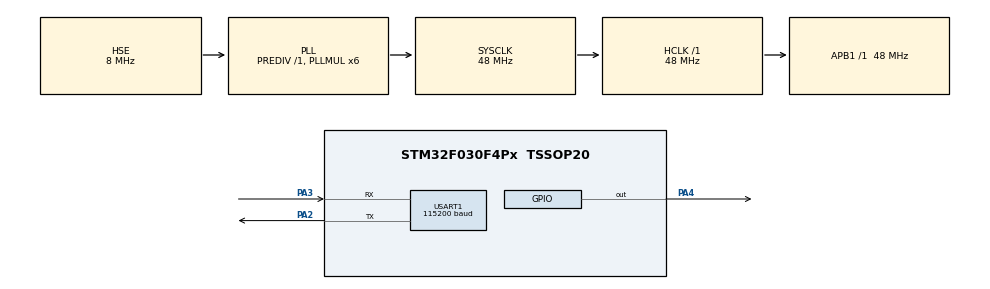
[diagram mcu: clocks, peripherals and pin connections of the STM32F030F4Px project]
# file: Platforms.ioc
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Mcu.Family=STM32F0
Mcu.Name=STM32F030F4Px
Mcu.Package=TSSOP20
NVIC.USART1_IRQn=true\:0\:0\:false
PA13.Mode=Serial-WireDebug
PA13.Signal=SYS_SWDIO
PA14.Mode=Serial-WireDebug
PA14.Signal=SYS_SWCLK
PA2.Mode=Asynchronous
PA2.Signal=USART1_TX
PA3.Mode=Asynchronous
PA3.Signal=USART1_RX
PA4.Signal=GPIO_Output
PF0-OSC_IN.Mode=HSE-External-Oscillator
PF0-OSC_IN.Signal=RCC_OSC_IN
PF1-OSC_OUT.Mode=HSE-External-Oscillator
PF1-OSC_OUT.Signal=RCC_OSC_OUT
ProjectManager.HeapSize=0x200
ProjectManager.StackSize=0x400
ProjectManager.TargetToolchain=MDK-ARM V5
RCC.AHBFreq_Value=48000000
RCC.APB1Freq_Value=48000000
RCC.APB1TimFreq_Value=48000000
RCC.HCLKFreq_Value=48000000
RCC.HSIState=RCC_HSI_ON
RCC.PLLMUL=RCC_PLL_MUL6
RCC.PLLSourceVirtual=RCC_PLLSOURCE_HSE
RCC.SYSCLKFreq_VALUE=48000000
RCC.SYSCLKSource=RCC_SYSCLKSOURCE_PLLCLK
USART1.BaudRate=115200
board=Platforms

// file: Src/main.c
/**
  ******************************************************************************
  * File Name          : main.c
  * Description        : Main program body
  ******************************************************************************
  *
  * COPYRIGHT(c) 2016 STMicroelectronics
  *
  * Redistribution and use in source and binary forms, with or without modification,
  * are permitted provided that the following conditions are met:
  *   1. Redistributions of source code must retain the above copyright notice,
  *      this list of conditions and the following disclaimer.
  *   2. Redistributions in binary form must reproduce the above copyright notice,
  *      this list of conditions and the following disclaimer in the documentation
  *      and/or other materials provided with the distribution.
  *   3. Neither the name of STMicroelectronics nor the names of its contributors
  *      may be used to endorse or promote products derived from this software
  *      without specific prior written permission.
  *
  * THIS SOFTWARE IS PROVIDED BY THE COPYRIGHT HOLDERS AND CONTRIBUTORS "AS IS"
  * AND ANY EXPRESS OR IMPLIED WARRANTIES, INCLUDING, BUT NOT LIMITED TO, THE
  * IMPLIED WARRANTIES OF MERCHANTABILITY AND FITNESS FOR A PARTICULAR PURPOSE ARE
  * DISCLAIMED. IN NO EVENT SHALL THE COPYRIGHT HOLDER OR CONTRIBUTORS BE LIABLE
  * FOR ANY DIRECT, INDIRECT, INCIDENTAL, SPECIAL, EXEMPLARY, OR CONSEQUENTIAL
  * DAMAGES (INCLUDING, BUT NOT LIMITED TO, PROCUREMENT OF SUBSTITUTE GOODS OR
  * SERVICES; LOSS OF USE, DATA, OR PROFITS; OR BUSINESS INTERRUPTION) HOWEVER
  * CAUSED AND ON ANY THEORY OF LIABILITY, WHETHER IN CONTRACT, STRICT LIABILITY,
  * OR TORT (INCLUDING NEGLIGENCE OR OTHERWISE) ARISING IN ANY WAY OUT OF THE USE
  * OF THIS SOFTWARE, EVEN IF ADVISED OF THE POSSIBILITY OF SUCH DAMAGE.
  *
  ******************************************************************************
  */
#include "stm32f0xx_hal.h"

/* USER CODE BEGIN Includes */
#include "main.h"

/* USER CODE END Includes */

UART_HandleTypeDef huart1;

/* USER CODE BEGIN PV */
/* Private variables ---------------------------------------------------------*/
#define APPLICATION_ADDRESS     (uint32_t)0x08001000
#define SYSCFG_MemoryRemap_SRAM                 ((uint8_t)0x03)
/* USER CODE END PV */

void SystemClock_Config(void);
static void MX_GPIO_Init(void);
static void MX_USART1_UART_Init(void);

/* USER CODE BEGIN PFP */
/* Private function prototypes -----------------------------------------------*/

/* USER CODE END PFP */

/* USER CODE BEGIN 0 */

#if   (defined ( __CC_ARM ))
  __IO uint32_t VectorTable[48] __attribute__((at(0x20000000)));
#elif (defined (__ICCARM__))
#pragma location = 0x20000000
  __no_init __IO uint32_t VectorTable[48];
#elif defined   (  __GNUC__  )
  __IO uint32_t VectorTable[48] __attribute__((section(".RAMVectorTable")));
#elif defined ( __TASKING__ )
  __IO uint32_t VectorTable[48] __at(0x20000000);
#endif

void NVIC_SRAM(void)
{
	for(uint8_t i = 0; i < 48; i++)
  {
    VectorTable[i] = *(__IO uint32_t*)(APPLICATION_ADDRESS + (i<<2));
  }

	uint32_t tmpctrl = 0;
  /* Get CFGR1 register value */
  tmpctrl = SYSCFG->CFGR1;

  /* Clear MEM_MODE bits */
  tmpctrl &= (uint32_t) (~SYSCFG_CFGR1_MEM_MODE);

  /* Set the new MEM_MODE bits value */
  tmpctrl |= (uint32_t) SYSCFG_MemoryRemap_SRAM;

  /* Set CFGR1 register with the new memory remap configuration */
  SYSCFG->CFGR1 = tmpctrl;
}

/* USER CODE END 0 */

int main(void)
{

  /* USER CODE BEGIN 1 */
	uint8_t temp = temp;
  /* USER CODE END 1 */

  /* MCU Configuration----------------------------------------------------------*/

  /* Reset of all peripherals, Initializes the Flash interface and the Systick. */
  HAL_Init();

  /* Configure the system clock */
//  SystemClock_Config();

  /* Initialize all configured peripherals */
  MX_GPIO_Init();
  MX_USART1_UART_Init();

  /* USER CODE BEGIN 2 */
	//这个函数必须要在APP中调用
	NVIC_SRAM();

  if(NVIC_GetPendingIRQ(SysTick_IRQn) != RESET)
  {
    HAL_NVIC_ClearPendingIRQ(SysTick_IRQn);
		HAL_UART_Transmit(&huart1,"SysTick_IRQn\r\n",14,10);
  }
  /* USER CODE END 2 */

  /* Infinite loop */
  while (1)
  {

  /* USER CODE BEGIN 3 */
		HAL_UART_Transmit(&huart1,"Successful and Happy\r\n",22,10);

		HAL_Delay(500);
  }
  /* USER CODE END 3 */

}

/** System Clock Configuration
*/
void SystemClock_Config(void)
{

  RCC_OscInitTypeDef RCC_OscInitStruct;
  RCC_ClkInitTypeDef RCC_ClkInitStruct;
  RCC_PeriphCLKInitTypeDef PeriphClkInit;

  RCC_OscInitStruct.OscillatorType = RCC_OSCILLATORTYPE_HSE;
  RCC_OscInitStruct.HSEState = RCC_HSE_ON;
  RCC_OscInitStruct.PLL.PLLState = RCC_PLL_ON;
  RCC_OscInitStruct.PLL.PLLSource = RCC_PLLSOURCE_HSE;
  RCC_OscInitStruct.PLL.PLLMUL = RCC_PLL_MUL6;
  RCC_OscInitStruct.PLL.PREDIV = RCC_PREDIV_DIV1;
  HAL_RCC_OscConfig(&RCC_OscInitStruct);

  RCC_ClkInitStruct.ClockType = RCC_CLOCKTYPE_SYSCLK;
  RCC_ClkInitStruct.SYSCLKSource = RCC_SYSCLKSOURCE_PLLCLK;
  RCC_ClkInitStruct.AHBCLKDivider = RCC_SYSCLK_DIV1;
  RCC_ClkInitStruct.APB1CLKDivider = RCC_HCLK_DIV1;
  HAL_RCC_ClockConfig(&RCC_ClkInitStruct, FLASH_LATENCY_1);

  PeriphClkInit.PeriphClockSelection = RCC_PERIPHCLK_USART1;
  PeriphClkInit.Usart1ClockSelection = RCC_USART1CLKSOURCE_PCLK1;
  HAL_RCCEx_PeriphCLKConfig(&PeriphClkInit);

  HAL_SYSTICK_Config(HAL_RCC_GetHCLKFreq()/1000);

  HAL_SYSTICK_CLKSourceConfig(SYSTICK_CLKSOURCE_HCLK);

  /* SysTick_IRQn interrupt configuration */
  HAL_NVIC_SetPriority(SysTick_IRQn, 0, 0);
}

/* USART1 init function */
void MX_USART1_UART_Init(void)
{

  huart1.Instance = USART1;
  huart1.Init.BaudRate = 115200;
  huart1.Init.WordLength = UART_WORDLENGTH_8B;
  huart1.Init.StopBits = UART_STOPBITS_1;
  huart1.Init.Parity = UART_PARITY_NONE;
  huart1.Init.Mode = UART_MODE_TX_RX;
  huart1.Init.HwFlowCtl = UART_HWCONTROL_NONE;
  huart1.Init.OverSampling = UART_OVERSAMPLING_16;
  huart1.Init.OneBitSampling = UART_ONEBIT_SAMPLING_DISABLED ;
  huart1.AdvancedInit.AdvFeatureInit = UART_ADVFEATURE_NO_INIT;
  HAL_UART_Init(&huart1);

}

/** Configure pins as
        * Analog
        * Input
        * Output
        * EVENT_OUT
        * EXTI
*/
void MX_GPIO_Init(void)
{

  GPIO_InitTypeDef GPIO_InitStruct;

  /* GPIO Ports Clock Enable */
  __GPIOF_CLK_ENABLE();
  __GPIOA_CLK_ENABLE();

  /*Configure GPIO pin : PA4 */
  GPIO_InitStruct.Pin = GPIO_PIN_4;
  GPIO_InitStruct.Mode = GPIO_MODE_OUTPUT_PP;
  GPIO_InitStruct.Pull = GPIO_NOPULL;
  GPIO_InitStruct.Speed = GPIO_SPEED_LOW;
  HAL_GPIO_Init(GPIOA, &GPIO_InitStruct);

}

/* USER CODE BEGIN 4 */
void HAL_SYSTICK_Callback(void)
{
//	static uint8_t temp=0;
//	temp++;
//	if(temp==0)
//	{
//		HAL_GPIO_TogglePin(GPIOA,GPIO_PIN_4);
//	}
}
/* USER CODE END 4 */

/************************ (C) COPYRIGHT STMicroelectronics *****END OF FILE****/
